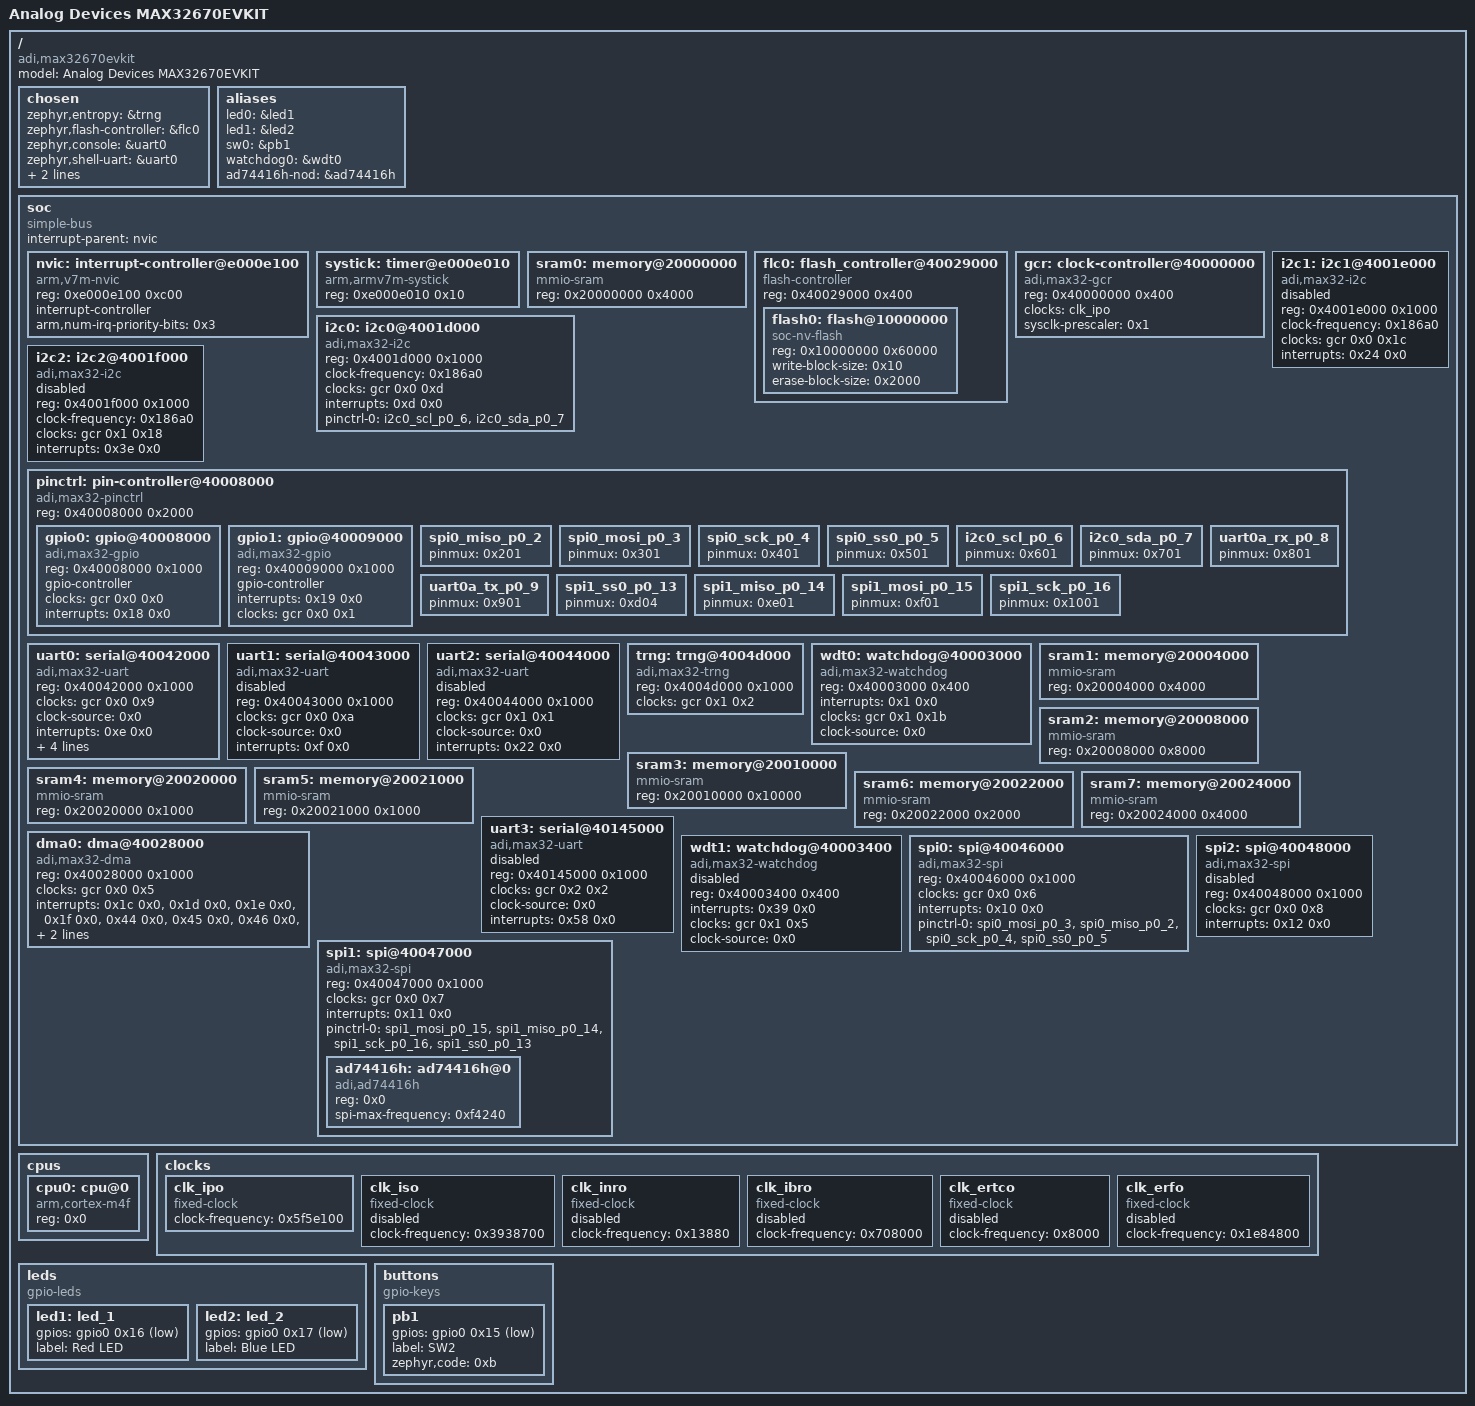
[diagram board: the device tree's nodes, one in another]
/dts-v1/;

/ {
	#address-cells = < 0x1 >;
	#size-cells = < 0x1 >;
	model = "Analog Devices MAX32670EVKIT";
	compatible = "adi,max32670evkit";
	chosen {
		zephyr,entropy = &trng;
		zephyr,flash-controller = &flc0;
		zephyr,console = &uart0;
		zephyr,shell-uart = &uart0;
		zephyr,sram = &sram3;
		zephyr,flash = &flash0;
	};
	aliases {
		led0 = &led1;
		led1 = &led2;
		sw0 = &pb1;
		watchdog0 = &wdt0;
		ad74416h-nod = &ad74416h;
	};
	soc {
		#address-cells = < 0x1 >;
		#size-cells = < 0x1 >;
		compatible = "simple-bus";
		interrupt-parent = < &nvic >;
		ranges;
		nvic: interrupt-controller@e000e100 {
			#address-cells = < 0x1 >;
			compatible = "arm,v7m-nvic";
			reg = < 0xe000e100 0xc00 >;
			interrupt-controller;
			#interrupt-cells = < 0x2 >;
			arm,num-irq-priority-bits = < 0x3 >;
			phandle = < 0x1 >;
		};
		systick: timer@e000e010 {
			compatible = "arm,armv7m-systick";
			reg = < 0xe000e010 0x10 >;
		};
		sram0: memory@20000000 {
			compatible = "mmio-sram";
			reg = < 0x20000000 0x4000 >;
		};
		flc0: flash_controller@40029000 {
			compatible = "flash-controller";
			reg = < 0x40029000 0x400 >;
			#address-cells = < 0x1 >;
			#size-cells = < 0x1 >;
			status = "okay";
			flash0: flash@10000000 {
				compatible = "soc-nv-flash";
				reg = < 0x10000000 0x60000 >;
				write-block-size = < 0x10 >;
				erase-block-size = < 0x2000 >;
			};
		};
		gcr: clock-controller@40000000 {
			reg = < 0x40000000 0x400 >;
			compatible = "adi,max32-gcr";
			#clock-cells = < 0x2 >;
			clocks = < &clk_ipo >;
			sysclk-prescaler = < 0x1 >;
			status = "okay";
			phandle = < 0x3 >;
		};
		i2c0: i2c0@4001d000 {
			compatible = "adi,max32-i2c";
			reg = < 0x4001d000 0x1000 >;
			#address-cells = < 0x1 >;
			#size-cells = < 0x0 >;
			clock-frequency = < 0x186a0 >;
			clocks = < &gcr 0x0 0xd >;
			interrupts = < 0xd 0x0 >;
			status = "okay";
			pinctrl-0 = < &i2c0_scl_p0_6 &i2c0_sda_p0_7 >;
			pinctrl-names = "default";
		};
		i2c1: i2c1@4001e000 {
			compatible = "adi,max32-i2c";
			reg = < 0x4001e000 0x1000 >;
			#address-cells = < 0x1 >;
			#size-cells = < 0x0 >;
			clock-frequency = < 0x186a0 >;
			clocks = < &gcr 0x0 0x1c >;
			interrupts = < 0x24 0x0 >;
			status = "disabled";
		};
		i2c2: i2c2@4001f000 {
			compatible = "adi,max32-i2c";
			reg = < 0x4001f000 0x1000 >;
			#address-cells = < 0x1 >;
			#size-cells = < 0x0 >;
			clock-frequency = < 0x186a0 >;
			clocks = < &gcr 0x1 0x18 >;
			interrupts = < 0x3e 0x0 >;
			status = "disabled";
		};
		pinctrl: pin-controller@40008000 {
			compatible = "adi,max32-pinctrl";
			#address-cells = < 0x1 >;
			#size-cells = < 0x1 >;
			reg = < 0x40008000 0x2000 >;
			gpio0: gpio@40008000 {
				reg = < 0x40008000 0x1000 >;
				compatible = "adi,max32-gpio";
				gpio-controller;
				#gpio-cells = < 0x2 >;
				clocks = < &gcr 0x0 0x0 >;
				interrupts = < 0x18 0x0 >;
				status = "okay";
				phandle = < 0x10 >;
			};
			gpio1: gpio@40009000 {
				reg = < 0x40009000 0x1000 >;
				compatible = "adi,max32-gpio";
				gpio-controller;
				#gpio-cells = < 0x2 >;
				interrupts = < 0x19 0x0 >;
				clocks = < &gcr 0x0 0x1 >;
				status = "okay";
			};
			spi0_miso_p0_2: spi0_miso_p0_2 {
				pinmux = < 0x201 >;
				phandle = < 0x9 >;
			};
			spi0_mosi_p0_3: spi0_mosi_p0_3 {
				pinmux = < 0x301 >;
				phandle = < 0x8 >;
			};
			spi0_sck_p0_4: spi0_sck_p0_4 {
				pinmux = < 0x401 >;
				phandle = < 0xa >;
			};
			spi0_ss0_p0_5: spi0_ss0_p0_5 {
				pinmux = < 0x501 >;
				phandle = < 0xb >;
			};
			i2c0_scl_p0_6: i2c0_scl_p0_6 {
				pinmux = < 0x601 >;
				phandle = < 0x4 >;
			};
			i2c0_sda_p0_7: i2c0_sda_p0_7 {
				pinmux = < 0x701 >;
				phandle = < 0x5 >;
			};
			uart0a_rx_p0_8: uart0a_rx_p0_8 {
				pinmux = < 0x801 >;
				phandle = < 0x7 >;
			};
			uart0a_tx_p0_9: uart0a_tx_p0_9 {
				pinmux = < 0x901 >;
				phandle = < 0x6 >;
			};
			spi1_ss0_p0_13: spi1_ss0_p0_13 {
				pinmux = < 0xd04 >;
				phandle = < 0xf >;
			};
			spi1_miso_p0_14: spi1_miso_p0_14 {
				pinmux = < 0xe01 >;
				phandle = < 0xd >;
			};
			spi1_mosi_p0_15: spi1_mosi_p0_15 {
				pinmux = < 0xf01 >;
				phandle = < 0xc >;
			};
			spi1_sck_p0_16: spi1_sck_p0_16 {
				pinmux = < 0x1001 >;
				phandle = < 0xe >;
			};
		};
		uart0: serial@40042000 {
			compatible = "adi,max32-uart";
			reg = < 0x40042000 0x1000 >;
			clocks = < &gcr 0x0 0x9 >;
			clock-source = < 0x0 >;
			interrupts = < 0xe 0x0 >;
			status = "okay";
			pinctrl-0 = < &uart0a_tx_p0_9 &uart0a_rx_p0_8 >;
			pinctrl-names = "default";
			current-speed = < 0x1c200 >;
			data-bits = < 0x8 >;
			parity = "none";
		};
		uart1: serial@40043000 {
			compatible = "adi,max32-uart";
			reg = < 0x40043000 0x1000 >;
			clocks = < &gcr 0x0 0xa >;
			clock-source = < 0x0 >;
			interrupts = < 0xf 0x0 >;
			status = "disabled";
		};
		uart2: serial@40044000 {
			compatible = "adi,max32-uart";
			reg = < 0x40044000 0x1000 >;
			clocks = < &gcr 0x1 0x1 >;
			clock-source = < 0x0 >;
			interrupts = < 0x22 0x0 >;
			status = "disabled";
		};
		trng: trng@4004d000 {
			compatible = "adi,max32-trng";
			reg = < 0x4004d000 0x1000 >;
			clocks = < &gcr 0x1 0x2 >;
			status = "okay";
		};
		wdt0: watchdog@40003000 {
			compatible = "adi,max32-watchdog";
			reg = < 0x40003000 0x400 >;
			interrupts = < 0x1 0x0 >;
			clocks = < &gcr 0x1 0x1b >;
			clock-source = < 0x0 >;
			status = "okay";
		};
		sram1: memory@20004000 {
			compatible = "mmio-sram";
			reg = < 0x20004000 0x4000 >;
		};
		sram2: memory@20008000 {
			compatible = "mmio-sram";
			reg = < 0x20008000 0x8000 >;
		};
		sram3: memory@20010000 {
			compatible = "mmio-sram";
			reg = < 0x20010000 0x10000 >;
		};
		sram4: memory@20020000 {
			compatible = "mmio-sram";
			reg = < 0x20020000 0x1000 >;
		};
		sram5: memory@20021000 {
			compatible = "mmio-sram";
			reg = < 0x20021000 0x1000 >;
		};
		sram6: memory@20022000 {
			compatible = "mmio-sram";
			reg = < 0x20022000 0x2000 >;
		};
		sram7: memory@20024000 {
			compatible = "mmio-sram";
			reg = < 0x20024000 0x4000 >;
		};
		uart3: serial@40145000 {
			compatible = "adi,max32-uart";
			reg = < 0x40145000 0x1000 >;
			clocks = < &gcr 0x2 0x2 >;
			clock-source = < 0x0 >;
			interrupts = < 0x58 0x0 >;
			status = "disabled";
		};
		dma0: dma@40028000 {
			compatible = "adi,max32-dma";
			reg = < 0x40028000 0x1000 >;
			clocks = < &gcr 0x0 0x5 >;
			interrupts = < 0x1c 0x0 >, < 0x1d 0x0 >, < 0x1e 0x0 >, < 0x1f 0x0 >, < 0x44 0x0 >, < 0x45 0x0 >, < 0x46 0x0 >, < 0x47 0x0 >;
			dma-channels = < 0x8 >;
			status = "okay";
			#dma-cells = < 0x2 >;
		};
		wdt1: watchdog@40003400 {
			compatible = "adi,max32-watchdog";
			reg = < 0x40003400 0x400 >;
			interrupts = < 0x39 0x0 >;
			clocks = < &gcr 0x1 0x5 >;
			clock-source = < 0x0 >;
			status = "disabled";
		};
		spi0: spi@40046000 {
			compatible = "adi,max32-spi";
			reg = < 0x40046000 0x1000 >;
			#address-cells = < 0x1 >;
			#size-cells = < 0x0 >;
			clocks = < &gcr 0x0 0x6 >;
			interrupts = < 0x10 0x0 >;
			status = "okay";
			pinctrl-0 = < &spi0_mosi_p0_3 &spi0_miso_p0_2 &spi0_sck_p0_4 &spi0_ss0_p0_5 >;
			pinctrl-names = "default";
		};
		spi1: spi@40047000 {
			compatible = "adi,max32-spi";
			reg = < 0x40047000 0x1000 >;
			#address-cells = < 0x1 >;
			#size-cells = < 0x0 >;
			clocks = < &gcr 0x0 0x7 >;
			interrupts = < 0x11 0x0 >;
			status = "okay";
			pinctrl-0 = < &spi1_mosi_p0_15 &spi1_miso_p0_14 &spi1_sck_p0_16 &spi1_ss0_p0_13 >;
			pinctrl-names = "default";
			ad74416h: ad74416h@0 {
				compatible = "adi,ad74416h";
				reg = < 0x0 >;
				spi-max-frequency = < 0xf4240 >;
				status = "okay";
			};
		};
		spi2: spi@40048000 {
			compatible = "adi,max32-spi";
			reg = < 0x40048000 0x1000 >;
			#address-cells = < 0x1 >;
			#size-cells = < 0x0 >;
			clocks = < &gcr 0x0 0x8 >;
			interrupts = < 0x12 0x0 >;
			status = "disabled";
		};
	};
	cpus {
		#address-cells = < 0x1 >;
		#size-cells = < 0x0 >;
		cpu0: cpu@0 {
			device_type = "cpu";
			compatible = "arm,cortex-m4f";
			reg = < 0x0 >;
		};
	};
	clocks {
		clk_ipo: clk_ipo {
			compatible = "fixed-clock";
			#clock-cells = < 0x0 >;
			clock-frequency = < 0x5f5e100 >;
			status = "okay";
			phandle = < 0x2 >;
		};
		clk_iso: clk_iso {
			compatible = "fixed-clock";
			#clock-cells = < 0x0 >;
			clock-frequency = < 0x3938700 >;
			status = "disabled";
		};
		clk_inro: clk_inro {
			compatible = "fixed-clock";
			#clock-cells = < 0x0 >;
			clock-frequency = < 0x13880 >;
			status = "disabled";
		};
		clk_ibro: clk_ibro {
			compatible = "fixed-clock";
			#clock-cells = < 0x0 >;
			clock-frequency = < 0x708000 >;
			status = "disabled";
		};
		clk_ertco: clk_ertco {
			compatible = "fixed-clock";
			#clock-cells = < 0x0 >;
			clock-frequency = < 0x8000 >;
			status = "disabled";
		};
		clk_erfo: clk_erfo {
			compatible = "fixed-clock";
			#clock-cells = < 0x0 >;
			clock-frequency = < 0x1e84800 >;
			status = "disabled";
		};
	};
	leds {
		compatible = "gpio-leds";
		led1: led_1 {
			gpios = < &gpio0 0x16 0x1 >;
			label = "Red LED";
		};
		led2: led_2 {
			gpios = < &gpio0 0x17 0x1 >;
			label = "Blue LED";
		};
	};
	buttons {
		compatible = "gpio-keys";
		pb1: pb1 {
			gpios = < &gpio0 0x15 0x11 >;
			label = "SW2";
			zephyr,code = < 0xb >;
		};
	};
};
